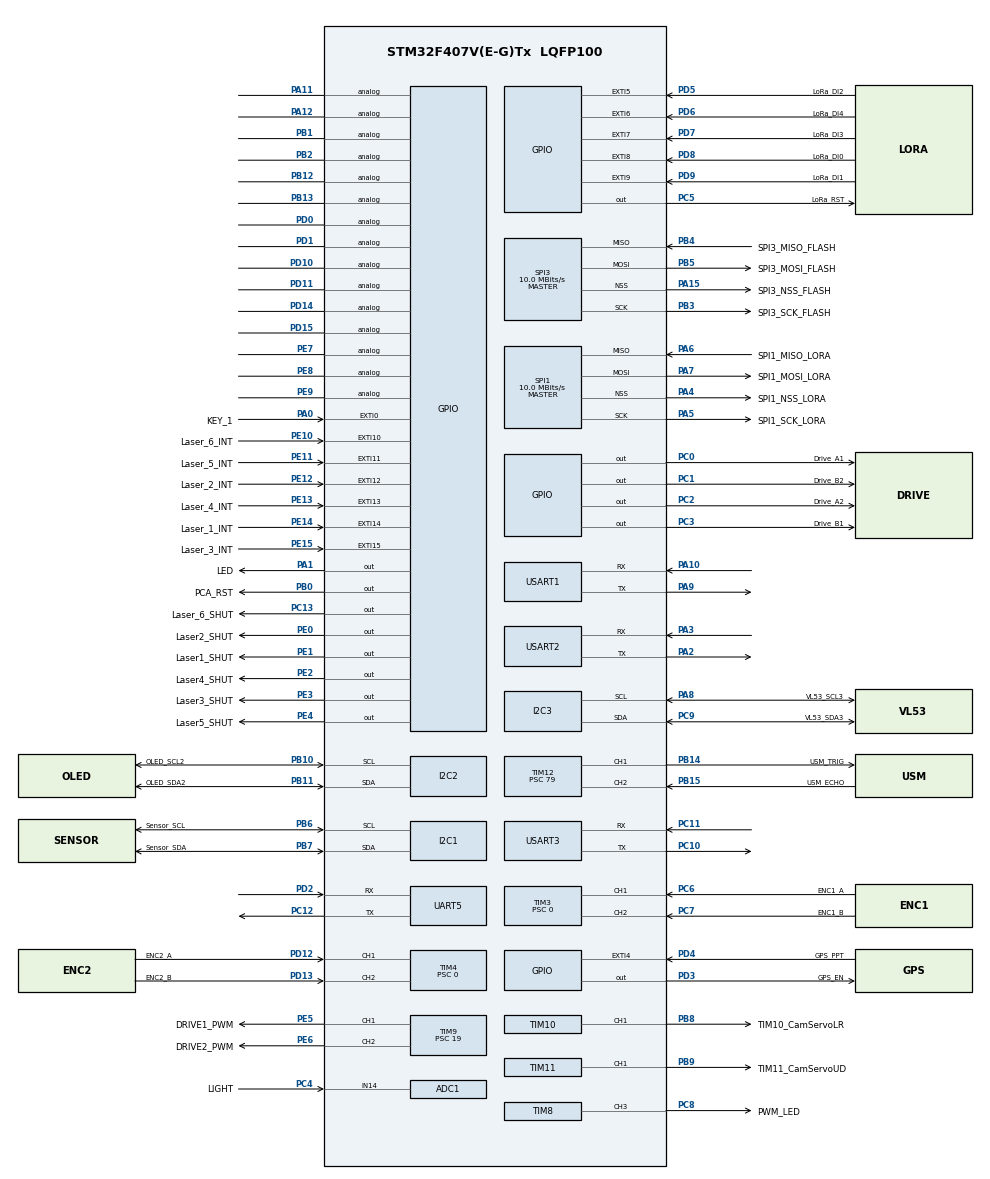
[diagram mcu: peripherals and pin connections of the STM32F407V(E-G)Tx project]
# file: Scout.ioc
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ADC1.Channel-1\#ChannelRegularConversion=ADC_CHANNEL_14
ADC1.Channel-4\#ChannelRegularConversion=ADC_CHANNEL_TEMPSENSOR
ADC1.Channel-5\#ChannelRegularConversion=ADC_CHANNEL_VREFINT
ADC1.ClockPrescaler=ADC_CLOCK_SYNC_PCLK_DIV8
ADC1.ContinuousConvMode=ENABLE
ADC1.InjNumberOfConversion=0
ADC1.NbrOfConversion=3
ADC1.NbrOfConversionFlag=1
ADC1.Rank-1\#ChannelRegularConversion=1
ADC1.Rank-4\#ChannelRegularConversion=2
ADC1.Rank-5\#ChannelRegularConversion=3
ADC1.SamplingTime-1\#ChannelRegularConversion=ADC_SAMPLETIME_28CYCLES
ADC1.SamplingTime-4\#ChannelRegularConversion=ADC_SAMPLETIME_28CYCLES
ADC1.SamplingTime-5\#ChannelRegularConversion=ADC_SAMPLETIME_28CYCLES
ADC1.master=1
I2C1.I2C_Mode=I2C_Fast
I2C2.I2C_Mode=I2C_Fast
I2C3.I2C_Mode=I2C_Fast
IWDG.Prescaler=IWDG_PRESCALER_16
IWDG.Reload=2000
Mcu.Family=STM32F4
Mcu.Name=STM32F407V(E-G)Tx
Mcu.Package=LQFP100
NVIC.ADC_IRQn=true\:0\:0\:false\:false\:true\:true\:true\:true
NVIC.EXTI0_IRQn=true\:15\:0\:true\:false\:true\:true\:true\:true
NVIC.EXTI15_10_IRQn=true\:5\:0\:true\:false\:true\:true\:true\:true
NVIC.EXTI9_5_IRQn=true\:5\:0\:true\:false\:true\:true\:true\:true
NVIC.HASH_RNG_IRQn=true\:9\:0\:true\:false\:true\:true\:true\:true
NVIC.I2C1_ER_IRQn=true\:3\:0\:true\:false\:true\:true\:true\:true
NVIC.I2C1_EV_IRQn=true\:0\:0\:false\:false\:true\:true\:true\:true
NVIC.I2C2_ER_IRQn=true\:3\:0\:true\:false\:true\:true\:true\:true
NVIC.I2C2_EV_IRQn=true\:0\:0\:false\:false\:true\:true\:true\:true
NVIC.I2C3_ER_IRQn=true\:3\:0\:true\:false\:true\:true\:true\:true
NVIC.I2C3_EV_IRQn=true\:0\:0\:false\:false\:true\:true\:true\:true
NVIC.PriorityGroup=NVIC_PRIORITYGROUP_4
NVIC.SPI1_IRQn=true\:1\:0\:true\:false\:true\:true\:true\:true
NVIC.SPI3_IRQn=true\:1\:0\:true\:false\:true\:true\:true\:true
NVIC.TIM1_BRK_TIM9_IRQn=true\:6\:0\:true\:false\:true\:true\:true\:true
NVIC.TIM1_TRG_COM_TIM11_IRQn=true\:7\:0\:true\:false\:true\:true\:true\:true
NVIC.TIM1_UP_TIM10_IRQn=true\:7\:0\:true\:false\:true\:true\:true\:true
NVIC.TIM6_DAC_IRQn=true\:6\:0\:true\:false\:true\:true\:true\:true
NVIC.TIM7_IRQn=true\:6\:0\:true\:false\:true\:true\:true\:true
NVIC.TIM8_BRK_TIM12_IRQn=true\:7\:0\:true\:false\:true\:true\:true\:true
NVIC.TIM8_TRG_COM_TIM14_IRQn=true\:0\:0\:false\:false\:true\:true\:true\:true
NVIC.TIM8_UP_TIM13_IRQn=true\:7\:0\:true\:false\:true\:true\:true\:true
NVIC.UART5_IRQn=true\:2\:0\:true\:false\:true\:true\:true\:true
NVIC.USART1_IRQn=true\:2\:0\:true\:false\:true\:true\:true\:true
NVIC.USART2_IRQn=true\:2\:0\:true\:false\:true\:true\:true\:true
NVIC.USART3_IRQn=true\:2\:0\:true\:false\:true\:true\:true\:true
PA0-WKUP.GPIO_Label=KEY_1
PA0-WKUP.GPIO_ModeDefaultEXTI=GPIO_MODE_IT_RISING
PA0-WKUP.GPIO_PuPd=GPIO_PULLDOWN
PA0-WKUP.Signal=GPXTI0
PA1.GPIO_Label=LED
PA1.GPIO_ModeDefaultOutputPP=GPIO_MODE_OUTPUT_OD
PA1.GPIO_PuPd=GPIO_NOPULL
PA1.PinState=GPIO_PIN_SET
PA1.Signal=GPIO_Output
PA10.Mode=Asynchronous
PA10.Signal=USART1_RX
PA11.Signal=GPIO_Analog
PA12.Signal=GPIO_Analog
PA13.Mode=Serial_Wire
PA13.Signal=SYS_JTMS-SWDIO
PA14.Mode=Serial_Wire
PA14.Signal=SYS_JTCK-SWCLK
PA15.GPIO_Label=SPI3_NSS_FLASH
PA15.Mode=NSS_Signal_Hard_Output
PA15.Signal=SPI3_NSS
PA2.Mode=Asynchronous
PA2.Signal=USART2_TX
PA3.Mode=Asynchronous
PA3.Signal=USART2_RX
PA4.GPIO_Label=SPI1_NSS_LORA
PA4.Mode=NSS_Signal_Hard_Output
PA4.Signal=SPI1_NSS
PA5.GPIO_Label=SPI1_SCK_LORA
PA5.Mode=Full_Duplex_Master
PA5.Signal=SPI1_SCK
PA6.GPIO_Label=SPI1_MISO_LORA
PA6.Mode=Full_Duplex_Master
PA6.Signal=SPI1_MISO
PA7.GPIO_Label=SPI1_MOSI_LORA
PA7.Mode=Full_Duplex_Master
PA7.Signal=SPI1_MOSI
PA8.GPIO_Label=VL53_SCL3
PA8.Mode=I2C
PA8.Signal=I2C3_SCL
PA9.Mode=Asynchronous
PA9.Signal=USART1_TX
PB0.GPIO_Label=PCA_RST
PB0.GPIO_PuPd=GPIO_PULLUP
PB0.PinState=GPIO_PIN_SET
PB0.Signal=GPIO_Output
PB1.Signal=GPIO_Analog
PB10.GPIO_Label=OLED_SCL2
PB10.Mode=I2C
PB10.Signal=I2C2_SCL
PB11.GPIO_Label=OLED_SDA2
PB11.Mode=I2C
PB11.Signal=I2C2_SDA
PB12.Signal=GPIO_Analog
PB13.Signal=GPIO_Analog
PB14.GPIO_Label=USM_TRIG
PB14.Signal=S_TIM12_CH1
PB15.GPIO_Label=USM_ECHO
PB15.Signal=S_TIM12_CH2
PB2.Signal=GPIO_Analog
PB3.GPIO_Label=SPI3_SCK_FLASH
PB3.Mode=Full_Duplex_Master
PB3.Signal=SPI3_SCK
PB4.GPIO_Label=SPI3_MISO_FLASH
PB4.Mode=Full_Duplex_Master
PB4.Signal=SPI3_MISO
PB5.GPIO_Label=SPI3_MOSI_FLASH
PB5.Mode=Full_Duplex_Master
PB5.Signal=SPI3_MOSI
PB6.GPIO_Label=Sensor_SCL
PB6.Mode=I2C
PB6.Signal=I2C1_SCL
PB7.GPIO_Label=Sensor_SDA
PB7.Mode=I2C
PB7.Signal=I2C1_SDA
PB8.GPIO_Label=TIM10_CamServoLR
PB8.Signal=S_TIM10_CH1
PB9.GPIO_Label=TIM11_CamServoUD
PB9.Signal=S_TIM11_CH1
PC0.GPIO_Label=Drive_A1
PC0.GPIO_PuPd=GPIO_PULLDOWN
PC0.Signal=GPIO_Output
PC1.GPIO_Label=Drive_B2
PC1.GPIO_PuPd=GPIO_PULLDOWN
PC1.Signal=GPIO_Output
PC10.Mode=Asynchronous
PC10.Signal=USART3_TX
PC11.Mode=Asynchronous
PC11.Signal=USART3_RX
PC12.GPIO_Speed=GPIO_SPEED_FREQ_HIGH
PC12.Mode=Asynchronous
PC12.Signal=UART5_TX
PC13-ANTI_TAMP.GPIO_Label=Laser_6_SHUT
PC13-ANTI_TAMP.GPIO_PuPd=GPIO_PULLUP
PC13-ANTI_TAMP.PinState=GPIO_PIN_SET
PC13-ANTI_TAMP.Signal=GPIO_Output
PC14-OSC32_IN.Mode=LSE-External-Oscillator
PC14-OSC32_IN.Signal=RCC_OSC32_IN
PC15-OSC32_OUT.Mode=LSE-External-Oscillator
PC15-OSC32_OUT.Signal=RCC_OSC32_OUT
PC2.GPIO_Label=Drive_A2
PC2.GPIO_PuPd=GPIO_PULLDOWN
PC2.Signal=GPIO_Output
PC3.GPIO_Label=Drive_B1
PC3.GPIO_PuPd=GPIO_PULLDOWN
PC3.Signal=GPIO_Output
PC4.GPIO_Label=LIGHT
PC4.Signal=ADCx_IN14
PC5.GPIO_Label=LoRa_RST
PC5.GPIO_PuPd=GPIO_PULLUP
PC5.PinState=GPIO_PIN_SET
PC5.Signal=GPIO_Output
PC6.GPIO_Label=ENC1_A
PC6.Signal=S_TIM3_CH1
PC7.GPIO_Label=ENC1_B
PC7.Signal=S_TIM3_CH2
PC8.GPIO_Label=PWM_LED
PC8.Signal=S_TIM8_CH3
PC9.GPIO_Label=VL53_SDA3
PC9.Mode=I2C
PC9.Signal=I2C3_SDA
PD0.Signal=GPIO_Analog
PD1.Signal=GPIO_Analog
PD10.Signal=GPIO_Analog
PD11.Signal=GPIO_Analog
PD12.GPIO_Label=ENC2_A
PD12.Signal=S_TIM4_CH1
PD13.GPIO_Label=ENC2_B
PD13.Signal=S_TIM4_CH2
PD14.Signal=GPIO_Analog
PD15.Signal=GPIO_Analog
PD2.GPIO_Speed=GPIO_SPEED_FREQ_HIGH
PD2.Mode=Asynchronous
PD2.Signal=UART5_RX
PD3.GPIO_Label=GPS_EN
PD3.GPIO_PuPd=GPIO_PULLUP
PD3.PinState=GPIO_PIN_SET
PD3.Signal=GPIO_Output
PD4.GPIO_Label=GPS_PPT
PD4.GPIO_ModeDefaultEXTI=GPIO_MODE_EVT_RISING
PD4.GPIO_PuPd=GPIO_PULLDOWN
PD4.Signal=GPXTI4
PD5.GPIO_Label=LoRa_DI2
PD5.GPIO_PuPd=GPIO_PULLDOWN
PD5.Signal=GPXTI5
PD6.GPIO_Label=LoRa_DI4
PD6.GPIO_PuPd=GPIO_PULLDOWN
PD6.Signal=GPXTI6
PD7.GPIO_Label=LoRa_DI3
PD7.GPIO_PuPd=GPIO_PULLDOWN
PD7.Signal=GPXTI7
PD8.GPIO_Label=LoRa_DI0
PD8.GPIO_PuPd=GPIO_PULLDOWN
PD8.Signal=GPXTI8
PD9.GPIO_Label=LoRa_DI1
PD9.GPIO_PuPd=GPIO_PULLDOWN
PD9.Signal=GPXTI9
PE0.GPIO_Label=Laser2_SHUT
PE0.GPIO_PuPd=GPIO_PULLUP
PE0.PinState=GPIO_PIN_SET
PE0.Signal=GPIO_Output
PE1.GPIO_Label=Laser1_SHUT
PE1.GPIO_PuPd=GPIO_PULLUP
PE1.PinState=GPIO_PIN_SET
PE1.Signal=GPIO_Output
PE10.GPIO_Label=Laser_6_INT
PE10.GPIO_PuPd=GPIO_PULLUP
PE10.Signal=GPXTI10
PE11.GPIO_Label=Laser_5_INT
PE11.GPIO_PuPd=GPIO_PULLUP
PE11.Signal=GPXTI11
PE12.GPIO_Label=Laser_2_INT
PE12.GPIO_PuPd=GPIO_PULLUP
PE12.Signal=GPXTI12
PE13.GPIO_Label=Laser_4_INT
PE13.GPIO_PuPd=GPIO_PULLUP
PE13.Signal=GPXTI13
PE14.GPIO_Label=Laser_1_INT
PE14.GPIO_PuPd=GPIO_PULLUP
PE14.Signal=GPXTI14
PE15.GPIO_Label=Laser_3_INT
PE15.GPIO_PuPd=GPIO_PULLUP
PE15.Signal=GPXTI15
PE2.GPIO_Label=Laser4_SHUT
PE2.GPIO_PuPd=GPIO_PULLUP
PE2.PinState=GPIO_PIN_SET
PE2.Signal=GPIO_Output
PE3.GPIO_Label=Laser3_SHUT
PE3.GPIO_PuPd=GPIO_PULLUP
PE3.PinState=GPIO_PIN_SET
PE3.Signal=GPIO_Output
PE4.GPIO_Label=Laser5_SHUT
PE4.GPIO_PuPd=GPIO_PULLUP
PE4.PinState=GPIO_PIN_SET
PE4.Signal=GPIO_Output
PE5.GPIO_Label=DRIVE1_PWM
PE5.Signal=S_TIM9_CH1
PE6.GPIO_Label=DRIVE2_PWM
PE6.Signal=S_TIM9_CH2
PE7.Signal=GPIO_Analog
PE8.Signal=GPIO_Analog
PE9.Signal=GPIO_Analog
PH0-OSC_IN.Mode=HSE-External-Oscillator
PH0-OSC_IN.Signal=RCC_OSC_IN
PH1-OSC_OUT.Mode=HSE-External-Oscillator
PH1-OSC_OUT.Signal=RCC_OSC_OUT
ProjectManager.HeapSize=0x200
ProjectManager.StackSize=0x400
ProjectManager.TargetToolchain=STM32CubeIDE
RCC.48MHZClocksFreq_Value=40000000
RCC.AHBFreq_Value=160000000
RCC.APB1CLKDivider=RCC_HCLK_DIV4
RCC.APB1Freq_Value=40000000
RCC.APB1TimFreq_Value=80000000
RCC.APB2CLKDivider=RCC_HCLK_DIV2
RCC.APB2Freq_Value=80000000
RCC.APB2TimFreq_Value=160000000
RCC.CortexFreq_Value=160000000
RCC.EnbaleCSS=true
RCC.HCLKFreq_Value=160000000
RCC.HSE_Timout=250
RCC.HSE_VALUE=8000000
RCC.HSI_VALUE=16000000
RCC.PLLM=8
RCC.PLLN=320
RCC.PLLQ=8
RCC.PLLSourceVirtual=RCC_PLLSOURCE_HSE
RCC.RCC_RTC_Clock_Source=RCC_RTCCLKSOURCE_LSE
RCC.RCC_RTC_Clock_SourceVirtual=RCC_RTCCLKSOURCE_LSI
RCC.RCC_RTC_Clock_Source_FROM_HSE=RCC_RTCCLKSOURCE_HSE_DIV28
RCC.SYSCLKFreq_VALUE=160000000
RCC.SYSCLKSource=RCC_SYSCLKSOURCE_PLLCLK
RCC.VCOOutputFreq_Value=320000000
SH.ADCx_IN14.0=ADC1_IN14,IN14
SH.S_TIM10_CH1.0=TIM10_CH1,PWM Generation1 CH1
SH.S_TIM11_CH1.0=TIM11_CH1,PWM Generation1 CH1
SH.S_TIM12_CH1.0=TIM12_CH1,PWM Generation1 CH1
SH.S_TIM12_CH2.0=TIM12_CH2,Input_Capture2_from_TI2
SH.S_TIM3_CH1.0=TIM3_CH1,Encoder_Interface
SH.S_TIM3_CH2.0=TIM3_CH2,Encoder_Interface
SH.S_TIM4_CH1.0=TIM4_CH1,Encoder_Interface
SH.S_TIM4_CH2.0=TIM4_CH2,Encoder_Interface
SH.S_TIM8_CH3.0=TIM8_CH3,PWM Generation3 CH3
SH.S_TIM9_CH1.0=TIM9_CH1,PWM Generation1 CH1
SH.S_TIM9_CH2.0=TIM9_CH2,PWM Generation2 CH2
SPI1.BaudRatePrescaler=SPI_BAUDRATEPRESCALER_8
SPI1.CLKPhase=SPI_PHASE_1EDGE
SPI1.CLKPolarity=SPI_POLARITY_LOW
SPI1.CalculateBaudRate=10.0 MBits/s
SPI1.Direction=SPI_DIRECTION_2LINES
SPI1.Mode=SPI_MODE_MASTER
SPI1.VirtualNSS=VM_NSSHARD
SPI1.VirtualType=VM_MASTER
SPI3.BaudRatePrescaler=SPI_BAUDRATEPRESCALER_4
SPI3.CalculateBaudRate=10.0 MBits/s
SPI3.Direction=SPI_DIRECTION_2LINES
SPI3.Mode=SPI_MODE_MASTER
SPI3.VirtualNSS=VM_NSSHARD
SPI3.VirtualType=VM_MASTER
TIM10.Channel=TIM_CHANNEL_1
TIM10.Period=39999
TIM10.Prescaler=79
TIM10.Pulse=2250
TIM11.Channel=TIM_CHANNEL_1
TIM11.Period=39999
TIM11.Prescaler=79
TIM11.Pulse=2250
TIM12.Channel-Input_Capture2_from_TI2=TIM_CHANNEL_2
TIM12.Channel-PWM\ Generation1\ CH1=TIM_CHANNEL_1
TIM12.Period=65535
TIM12.Prescaler=79
TIM12.Pulse-PWM\ Generation1\ CH1=1
TIM13.Channel=TIM_CHANNEL_1
TIM13.Period=49999
TIM13.Prescaler=159
TIM13.Pulse=24999
TIM3.AutoReloadPreload=TIM_AUTORELOAD_PRELOAD_DISABLE
TIM3.EncoderMode=TIM_ENCODERMODE_TI12
TIM3.IC1Filter=5
TIM3.IC2Filter=5
TIM3.Prescaler=0
TIM4.AutoReloadPreload=TIM_AUTORELOAD_PRELOAD_DISABLE
TIM4.EncoderMode=TIM_ENCODERMODE_TI12
TIM4.IC1Filter=5
TIM4.IC2Filter=5
TIM4.Prescaler=0
TIM6.Prescaler=79
TIM6.TIM_MasterOutputTrigger=TIM_TRGO_UPDATE
TIM7.AutoReloadPreload=TIM_AUTORELOAD_PRELOAD_ENABLE
TIM7.Period=49999
TIM7.Prescaler=1599
TIM7.TIM_MasterOutputTrigger=TIM_TRGO_UPDATE
TIM8.AutoReloadPreload=TIM_AUTORELOAD_PRELOAD_DISABLE
TIM8.Channel-PWM\ Generation3\ CH3=TIM_CHANNEL_3
TIM8.Period=1999
TIM8.Prescaler=39
TIM8.RepetitionCounter=4
TIM8.TIM_MasterOutputTrigger=TIM_TRGO_RESET
TIM8.TIM_MasterSlaveMode=TIM_MASTERSLAVEMODE_DISABLE
TIM9.Channel-PWM\ Generation1\ CH1=TIM_CHANNEL_1
TIM9.Channel-PWM\ Generation2\ CH2=TIM_CHANNEL_2
TIM9.Period=3999
TIM9.Prescaler=19
UART5.VirtualMode=Asynchronous
USART1.VirtualMode=VM_ASYNC
USART2.Parity=PARITY_EVEN
USART2.VirtualMode=VM_ASYNC
USART3.VirtualMode=VM_ASYNC
VP_ADC1_TempSens_Input.Mode=IN-TempSens
VP_ADC1_Vref_Input.Mode=IN-Vrefint
VP_CRC_VS_CRC.Mode=CRC_Activate
VP_IWDG_VS_IWDG.Mode=IWDG_Activate
VP_RNG_VS_RNG.Mode=RNG_Activate
VP_TIM10_VS_ClockSourceINT.Mode=Enable_Timer
VP_TIM11_VS_ClockSourceINT.Mode=Enable_Timer
VP_TIM12_VS_ClockSourceINT.Mode=Internal
VP_TIM12_VS_ClockSourceITR.Mode=TriggerSource_ITR2
VP_TIM12_VS_ControllerModeTrigger.Mode=Trigger Mode
VP_TIM12_VS_OPM.Mode=OPM_bit
VP_TIM13_VS_ClockSourceINT.Mode=Enable_Timer
VP_TIM13_VS_no_output1.Mode=Output Compare1 No Output
VP_TIM6_VS_ClockSourceINT.Mode=Enable_Timer
VP_TIM7_VS_ClockSourceINT.Mode=Enable_Timer
VP_TIM9_VS_ClockSourceINT.Mode=Internal
board=custom

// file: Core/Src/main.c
/* USER CODE BEGIN Header */
/**
 ******************************************************************************
 * @file           : main.c
 * @brief          : Main program body
 ******************************************************************************
 * @attention
 *
 * Copyright (c) 2023 STMicroelectronics.
 * All rights reserved.
 *
 * This software is licensed under terms that can be found in the LICENSE file
 * in the root directory of this software component.
 * If no LICENSE file comes with this software, it is provided AS-IS.
 *
 ******************************************************************************
 */
/* USER CODE END Header */
#include "main.h"
#include "adc.h"
#include "crc.h"
#include "i2c.h"
#include "iwdg.h"
#include "rng.h"
#include "spi.h"
#include "tim.h"
#include "usart.h"
#include "gpio.h"

/* USER CODE BEGIN Includes */
#include "Objects.h"
/* USER CODE END Includes */

/* USER CODE BEGIN PV */
//variables for time based-----------------------------------------------------
volatile uint32_t mainTimeTick = 0;

//variables for enable sensor request and other options------------------------
volatile uint32_t DevicesEnableMask = 0;
volatile uint32_t laserReqMask = 0;
uint32_t optionMask = 0;
//objects: IO ports
extern I2C_IRQ_Conn_t I2CSensors;		//i2c1 bus for sensors
extern I2C_IRQ_Conn_t I2CLasers;		//i2c3 bus for VL53L01 sensors
extern SPI_Conn_TWO_t SPI_LoRa;			//SPI1 for LoRa radio
extern SPI_Conn_TWO_t SPI_Flash;		//SPI3 for flash
extern USART_FullDuplex_t USART_Orange;	//usart1 bus for Orange Pi Zero2 connection
extern USART_FullDuplex_t USART_CLI;			//usart2 bus for external connection CLI
extern USART_FullDuplex_t USART_UNO;		//usart3 bus for external connection
extern USART_FullDuplex_t UART_GPS;				//uart5 bus for GPS connection
//sensors----------------------------------------------------------------------
extern TCA9548A_t tca9548;					//i2c multiplexer
extern VL53L0x_t LaserFrontLeft;		//laser sensor VL53L01 front left place
extern VL53L0x_t LaserFrontRight;		//laser sensor VL53L01 front left place
extern VL53L0x_t LaserMidLeft;			//laser sensor VL53L01 front left place
extern VL53L0x_t LaserMidRight;			//laser sensor VL53L01 front left place
extern VL53L0x_t LaserBackLeft;			//laser sensor VL53L01 front left place
extern VL53L0x_t LaserBackRight;		//laser sensor VL53L01 front left place
extern ADXL345_t adxl345;				//accelerometer
extern ITG3205_t itg3205;				//gyroscope
extern QMC5883L_t qmc5883; 				//magnetometer
extern BME280_t bme280;					//ambient sensor
extern INA219_t ina219;					//current voltage power sensor
extern HC_SR04_t USMrange;
//objects------------------------------------------------------------------------
extern Drive_t Drive;
extern PID_M_t PidMoto_L;
extern PID_M_t PidMoto_R;
extern PID_MF_t PidMotoFilter_L;
extern PID_MF_t PidMotoFilter_R;
Camera_t camera;		//camera's servo drives
uint16_t leftWheelPWM;
uint16_t rightWheelPWM;
Quaternion_t quatHabr;
EulerAngles_t angHabr;
Quaternion_t quatMadg;
EulerAngles_t angMadg;
Quaternion_t quatMah;
EulerAngles_t angMah;
FusionEuler euler;
FusionAhrs ahrs;

uint16_t headLightsLevel = 0;
uint16_t ambientLightLevel = 0;
uint16_t mcuTemp = 0;
uint16_t mcuVoltage = 0;
/* USER CODE END PV */

void SystemClock_Config(void);
/* USER CODE BEGIN PFP */
static inline void EnableOption(uint32_t reg, uint32_t option) {
	SET_BIT(reg, option);
}
static inline void DisableOption(uint32_t reg, uint32_t option) {
	CLEAR_BIT(reg, option);
}
static inline uint32_t IsOptionEnable(uint32_t reg, uint32_t option) {
	return reg & option;
}
uint16_t SideLightsControl(uint16_t ambient, uint8_t en);
void WheelStop(GPIO_TypeDef *port, uint32_t pin1, uint32_t pin2);
void WheelForward(GPIO_TypeDef *port, uint32_t pinA, uint32_t pinB);
void WheelBackward(GPIO_TypeDef *port, uint32_t pinA, uint32_t pinB);
/* USER CODE END PFP */

int main(void) {

	/* MCU Configuration--------------------------------------------------------*/

	/* Reset of all peripherals, Initializes the Flash interface and the Systick. */
	LL_APB2_GRP1_EnableClock(LL_APB2_GRP1_PERIPH_SYSCFG);
	LL_APB1_GRP1_EnableClock(LL_APB1_GRP1_PERIPH_PWR);

	/* System interrupt init*/
	NVIC_SetPriorityGrouping(NVIC_PRIORITYGROUP_4);

	/* Configure the system clock */
	SystemClock_Config();

	/* Initialize all configured peripherals */
	MX_GPIO_Init();
	MX_CRC_Init();
	MX_RNG_Init();
	MX_SPI1_Init();
	MX_SPI3_Init();
	MX_I2C1_Init();
	MX_I2C2_Init();
	MX_I2C3_Init();
	MX_USART1_UART_Init();
	MX_USART2_UART_Init();
	MX_USART3_UART_Init();
	MX_UART5_Init();
	MX_TIM3_Init();
	MX_TIM4_Init();
	MX_TIM9_Init();
	MX_TIM10_Init();
	MX_TIM11_Init();
	MX_TIM12_Init();
	MX_TIM8_Init();
	MX_TIM6_Init();
	MX_TIM7_Init();
	MX_TIM13_Init();
	MX_ADC1_Init();
	//MX_IWDG_Init();
	/* USER CODE BEGIN 2 */
	SysTick_Config(SystemCoreClock / 1000);	//1ms tick
	TIM10->CCR1 = camera.posH = Servo_Init(&camera.srvLR, SG90_MIN, SG90_MAX,
	    10);
	TIM11->CCR1 = camera.posV = Servo_Init(&camera.srvUD, SG90_MIN, SG90_MAX,
	    10);

	HardwareInit();

	PID_MotoInit(6, 16, 0.75, 25, &PidMoto_L);
	PID_MotoInit(6, 16, 0.75, 25, &PidMoto_R);

	uint8_t stbus;
	LL_GPIO_ResetOutputPin(Laser1_SHUT_GPIO_Port, Laser1_SHUT_Pin | Laser2_SHUT_Pin | Laser3_SHUT_Pin |
			Laser4_SHUT_Pin | Laser5_SHUT_Pin);
	LL_GPIO_ResetOutputPin(Laser6_SHUT_GPIO_Port, Laser6_SHUT_Pin);
	LL_mDelay(5);
	LL_GPIO_SetOutputPin(Laser1_SHUT_GPIO_Port, Laser1_SHUT_Pin | Laser2_SHUT_Pin | Laser3_SHUT_Pin |
			Laser4_SHUT_Pin | Laser5_SHUT_Pin);
	LL_GPIO_SetOutputPin(Laser6_SHUT_GPIO_Port, Laser6_SHUT_Pin);
	LL_mDelay(5);
	do {
		stbus = TCA9548A_SetChannels(&I2CLasers, &tca9548, ~(TCA9548A_CH0 || TCA9548A_CH1 || TCA9548A_CH2 || TCA9548A_CH3 ||
		    TCA9548A_CH4 || TCA9548A_CH5 || TCA9548A_CH6 || TCA9548A_CH7));
	} while (!stbus);			// init i2c multiplexor
	do {
		stbus = TCA9548A_SetChannels(&I2CLasers, &tca9548, TCA9548A_CH0);
	} while (!stbus);	// enable channel 0

	/*do {
		stbus = VL53L0x_Init(&I2CLasers, &LaserBackLeft);
	} while (!stbus);	*/			// init laser back left
	do {
		stbus = TCA9548A_SetChannels(&I2CLasers, &tca9548, TCA9548A_CH1);
	} while (!stbus);	// enable channel 1
	/*do {
		stbus = VL53L0x_Init(&I2CLasers, &LaserBackRight);
	} while (!stbus);	*/			// init laser back right
	do {
		stbus = TCA9548A_SetChannels(&I2CLasers, &tca9548, TCA9548A_CH2);
	} while (!stbus);	// enable channel 2
	/*do {
		stbus = VL53L0x_Init(&I2CLasers, &LaserMidRight);
	} while (!stbus);		*/		// init laser mid right
	do {
		stbus = TCA9548A_SetChannels(&I2CLasers, &tca9548, TCA9548A_CH3);
	} while (!stbus);	// enable channel 3
	/*do {
		stbus = VL53L0x_Init(&I2CLasers, &LaserFrontRight);
	} while (!stbus);	*/			// init laser front right
	do {
		stbus = TCA9548A_SetChannels(&I2CLasers, &tca9548, TCA9548A_CH4);
	} while (!stbus);	// enable channel 4
	/*do {
		stbus = VL53L0x_Init(&I2CLasers, &LaserFrontLeft);
	} while (!stbus);	*/			// init laser front left
	do {
		stbus = TCA9548A_SetChannels(&I2CLasers, &tca9548, TCA9548A_CH5);
	} while (!stbus);	// enable channel 5
	/*do {
		stbus = VL53L0x_Init(&I2CLasers, &LaserMidLeft);
	} while (!stbus);*/				// init laser mid left
	/*do {
		stbus = ADXL345_Init(&I2CSensors, &adxl345);
	} while (!stbus);			// init accelerometer pass
	do {
		stbus = QMC5883L_Init(&I2CSensors, &qmc5883);
	} while (!stbus);		// init magnetometer pass
	do {
		stbus = ITG3205_Init(&I2CSensors, &itg3205);
	} while (!stbus);			// init gyroscope

	do {
		stbus = INA219_Init(&I2CSensors, &ina219);
	} while (!stbus);				// init power sensor
	do {
		stbus = BME280_Init(&I2CSensors, &bme280);
	} while (!stbus);				// init ambient sensor pass

	FusionAhrsInitialise(&ahrs);*/
	/* USER CODE END 2 */

	/* Infinite loop */
	/* USER CODE BEGIN WHILE */
	while (1) {

		/*if (laserReqMask) {
			switch (laserReqMask) {
			case 1:	// enable channel 0
				if (TCA9548A_SetChannels(&I2CLasers, &tca9548, TCA9548A_CH0)) {
					laserReqMask = 2;
				}
				break;
			case 2:
				if (VL53_ReadRangeSingle(&I2CLasers, &LaserBackLeft)) {
					laserReqMask = 6;
				}
				break;
			case 3:	//
				if (VL53_StartContinuous(&I2CLasers, &LaserBackLeft, 30)) {
					laserReqMask = 4;
				}
				break;
			case 4:
				if (VL53_readRangeContinuousMillimeters(&I2CLasers, &LaserBackLeft)) {
					laserReqMask = 5;
				}
				break;
			case 5:
				if (VL53_StopContinuous(&I2CLasers, &LaserBackLeft)) {
					laserReqMask = 6;
				}
				break;
			case 6:	// enable channel 1
				if (TCA9548A_SetChannels(&I2CLasers, &tca9548, TCA9548A_CH1)) {
					laserReqMask = 7;
				}
				break;
			case 7:
				if (VL53_ReadRangeSingle(&I2CLasers, &LaserBackRight)) {
					laserReqMask = 11;
				}
				break;
			case 8:
				if (VL53_StartContinuous(&I2CLasers, &LaserBackRight, 30)) {
					laserReqMask = 9;
				}
				break;
			case 9:
				if (VL53_readRangeContinuousMillimeters(&I2CLasers, &LaserBackRight)) {
					laserReqMask = 10;
				}
				break;
			case 10:
				if (VL53_StopContinuous(&I2CLasers, &LaserBackRight)) {
					laserReqMask = 11;
				}
				break;
			case 11:	// enable channel 2
				if (TCA9548A_SetChannels(&I2CLasers, &tca9548, TCA9548A_CH2)) {
					laserReqMask = 12;
				}
				break;
			case 12:
				if (VL53_ReadRangeSingle(&I2CLasers, &LaserMidRight)) {
					laserReqMask = 16;
				}
				break;
			case 13:	// init laser mid right
				if (VL53_StartContinuous(&I2CLasers, &LaserMidRight, 30)) {
					laserReqMask = 14;
				}
				break;
			case 14:
				if (VL53_readRangeContinuousMillimeters(&I2CLasers, &LaserMidRight)) {
					laserReqMask = 15;
				}
				break;
			case 15:
				if (VL53_StopContinuous(&I2CLasers, &LaserMidRight)) {
					laserReqMask = 16;
				}
				break;
			case 16:	// enable channel 3
				if (TCA9548A_SetChannels(&I2CLasers, &tca9548, TCA9548A_CH3)) {
					laserReqMask = 17;
				}
				break;
			case 17:
				if (VL53_ReadRangeSingle(&I2CLasers, &LaserFrontRight)) {
					laserReqMask = 21;
				}
				break;
			case 18:	// init laser front right
				if (VL53_StartContinuous(&I2CLasers, &LaserFrontRight, 30)) {
					laserReqMask = 19;
				}
				break;
			case 19:
				if (VL53_readRangeContinuousMillimeters(&I2CLasers, &LaserFrontRight)) {
					laserReqMask = 20;
				}
				break;
			case 20:
				if (VL53_StopContinuous(&I2CLasers, &LaserFrontRight)) {
					laserReqMask = 21;
				}
				break;
			case 21:	// enable channel 4
				if (TCA9548A_SetChannels(&I2CLasers, &tca9548, TCA9548A_CH4)) {
					laserReqMask = 22;
				}
				break;
			case 22:
				if (VL53_ReadRangeSingle(&I2CLasers, &LaserFrontLeft)) {
					laserReqMask = 26;
				}
				break;
			case 23:	// init laser front left
				if (VL53_StartContinuous(&I2CLasers, &LaserFrontLeft, 30)) {
					laserReqMask = 24;
				}
				break;
			case 24:
				if (VL53_readRangeContinuousMillimeters(&I2CLasers, &LaserFrontLeft)) {
					laserReqMask = 25;
				}
				break;
			case 25:
				if (VL53_StopContinuous(&I2CLasers, &LaserFrontLeft)) {
					laserReqMask = 26;
				}
				break;
			case 26:	// enable channel 5
				if (TCA9548A_SetChannels(&I2CLasers, &tca9548, TCA9548A_CH5)) {
					laserReqMask = 27;
				}
				break;
			case 27:
				if (VL53_ReadRangeSingle(&I2CLasers, &LaserMidLeft)) {
					laserReqMask = 0;
				}
				break;
			case 28:	// init laser front left
				if (VL53_StartContinuous(&I2CLasers, &LaserMidLeft, 30)) {
					laserReqMask = 29;
				}
				break;
			case 29:
				if (VL53_readRangeContinuousMillimeters(&I2CLasers, &LaserMidLeft)) {
					laserReqMask = 30;
				}
				break;
			case 30:
				if (VL53_StopContinuous(&I2CLasers, &LaserMidLeft)) {
					laserReqMask = 0;
				}
				break;
			default:
				laserReqMask = 0;
				break;
			}
		}
*/
		/*if (IsOptionEnable(DevicesEnableMask, ADXL_REQ_MASK)) {
			uint8_t st;
			st = ADXL345_GetData(&I2CSensors, &adxl345);
			if (st) {
				DisableOption(DevicesEnableMask, ADXL_REQ_MASK);
				EnableOption(DevicesEnableMask, QMC_REQ_MASK);
			}
		}
		if (IsOptionEnable(DevicesEnableMask, ITG_REQ_MASK)) {
			uint8_t st;
			st = ITG3205_GetData(&I2CSensors, &itg3205);
			if (st) {
				DisableOption(DevicesEnableMask, ITG_REQ_MASK);
				EnableOption(DevicesEnableMask, QMC_REQ_MASK);
			}
		}
		if (IsOptionEnable(DevicesEnableMask, QMC_REQ_MASK)) {
			uint8_t st;
			st = QMC5883L_GetData(&I2CSensors, &qmc5883);
			if (st) {
				quatMadg = MadgwickAHRSupdate(itg3205.data.X, itg3205.data.Y, -itg3205.data.Z,
														adxl345.data.X, adxl345.data.Y, adxl345.data.Z,
														qmc5883.data.X, qmc5883.data.Y, qmc5883.data.Z);
				angMadg = ToEulerAngles(quatMadg, 1);

				quatMah = MahonyAHRSupdate(itg3205.data.X, itg3205.data.Y, -itg3205.data.Z,
					adxl345.data.X, adxl345.data.Y, adxl345.data.Z,
					qmc5883.data.X, qmc5883.data.Y, qmc5883.data.Z);
				angMah = ToEulerAngles(quatMah, 1);
				quatHabr = AHRSUpdate9(itg3205.data.X, itg3205.data.Y, -itg3205.data.Z,
														adxl345.data.X, adxl345.data.Y, adxl345.data.Z,
														qmc5883.data.X, qmc5883.data.Y, qmc5883.data.Z, 0.05);
				angHabr = ToEulerAngles(quatHabr, 1);
				FusionVector gyro;
				gyro.axis.x = itg3205.data.X;
				gyro.axis.y = itg3205.data.Y;
				gyro.axis.z = -itg3205.data.Z;
				FusionVector accel;
				accel.axis.x = RadiansToDegrees(adxl345.data.X);
				accel.axis.y = RadiansToDegrees(adxl345.data.Y);
				accel.axis.z = RadiansToDegrees(adxl345.data.Z);
				FusionVector mag;
				mag.axis.x = qmc5883.data.X;
				mag.axis.y = qmc5883.data.Y;
				mag.axis.z = qmc5883.data.Z;
				FusionAhrsUpdate(&ahrs, gyro, accel, mag, 0.05);
				euler = FusionQuaternionToEuler(FusionAhrsGetQuaternion(&ahrs));
				DisableOption(DevicesEnableMask, QMC_REQ_MASK);
			}
		}*/
		/*if (IsOptionEnable(DevicesEnableMask, BME_REQ_MASK)) {
			uint8_t st;
			st = BME280_GetData(&I2CSensors, &bme280);
			if (st) {
				DisableOption(DevicesEnableMask, BME_REQ_MASK);
			}
		}
		if (IsOptionEnable(DevicesEnableMask, INA_REQ_MASK)) {
			uint8_t st;
			st = INA219_GetData(&I2CSensors, &ina219);
			if (st) {
				DisableOption(DevicesEnableMask, INA_REQ_MASK);
			}
		}*/
		Drive.SP.pwmLeft = 80;
		Drive.SP.pwmRight = 80;
		Drive.WL.speedSP = WheelSpeedZeroLimiter(Drive.WL.speedSP, Drive.SP.pwmLeft, 20.0, 25.0);
		Drive.WR.speedSP = WheelSpeedZeroLimiter(Drive.WR.speedSP, Drive.SP.pwmRight, 20.0, 25.0);
		WheelForward(Drive_A1_GPIO_Port, Drive_A1_Pin, Drive_A2_Pin);
		WheelForward(Drive_B1_GPIO_Port, Drive_B1_Pin, Drive_B2_Pin);

		TIM8->CCR3 = headLightsLevel = SideLightsControl(ambientLightLevel, 1);
		//CCR1 - right
		//CCR2 - left
		/* USER CODE END WHILE */

		/* USER CODE BEGIN 3 */
		LL_IWDG_ReloadCounter(IWDG);
	}
	/* USER CODE END 3 */
}

void SystemClock_Config(void) {
	LL_FLASH_SetLatency(LL_FLASH_LATENCY_5);
	while (LL_FLASH_GetLatency() != LL_FLASH_LATENCY_5) {
	}
	LL_PWR_SetRegulVoltageScaling(LL_PWR_REGU_VOLTAGE_SCALE1);
	LL_RCC_HSE_Enable();

	/* Wait till HSE is ready */
	while (LL_RCC_HSE_IsReady() != 1) {

	}
	LL_RCC_LSI_Enable();

	/* Wait till LSI is ready */
	while (LL_RCC_LSI_IsReady() != 1) {

	}
	LL_RCC_HSE_EnableCSS();
	LL_RCC_PLL_ConfigDomain_SYS(LL_RCC_PLLSOURCE_HSE, LL_RCC_PLLM_DIV_8, 320,
	LL_RCC_PLLP_DIV_2);
	LL_RCC_PLL_ConfigDomain_48M(LL_RCC_PLLSOURCE_HSE, LL_RCC_PLLM_DIV_8, 320,
	LL_RCC_PLLQ_DIV_8);
	LL_RCC_PLL_Enable();

	/* Wait till PLL is ready */
	while (LL_RCC_PLL_IsReady() != 1) {

	}
	while (LL_PWR_IsActiveFlag_VOS() == 0) {
	}
	LL_RCC_SetAHBPrescaler(LL_RCC_SYSCLK_DIV_1);
	LL_RCC_SetAPB1Prescaler(LL_RCC_APB1_DIV_4);
	LL_RCC_SetAPB2Prescaler(LL_RCC_APB2_DIV_2);
	LL_RCC_SetSysClkSource(LL_RCC_SYS_CLKSOURCE_PLL);

	/* Wait till System clock is ready */
	while (LL_RCC_GetSysClkSource() != LL_RCC_SYS_CLKSOURCE_STATUS_PLL) {

	}
	LL_Init1msTick(160000000);
	LL_SetSystemCoreClock(160000000);
}

/* USER CODE BEGIN 4 */
uint16_t SideLightsControl(uint16_t ambient, uint8_t en) {
	if (en) {
		return 500;
	} else {
		return 0;
	}
}

void WheelStop(GPIO_TypeDef *port, uint32_t pin1, uint32_t pin2) {
	LL_GPIO_ResetOutputPin(port, pin1 | pin2);
}

void WheelForward(GPIO_TypeDef *port, uint32_t pin1, uint32_t pin2) {
	LL_GPIO_ResetOutputPin(port, pin2);
	LL_GPIO_SetOutputPin(port, pin1);
}
void WheelBackward(GPIO_TypeDef *port, uint32_t pin1, uint32_t pin2) {
	LL_GPIO_ResetOutputPin(port, pin1);
	LL_GPIO_SetOutputPin(port, pin2);
}

void HardwareInit(void) {

	TIM3->CCER |= TIM_CCER_CC1E | TIM_CCER_CC2E;
	TIM3->CR1 |= TIM_CR1_CEN;

	TIM4->CCER |= TIM_CCER_CC1E | TIM_CCER_CC2E;
	TIM4->CR1 |= TIM_CR1_CEN;

	TIM7->DIER |= TIM_DIER_UIE;
	TIM7->CR1 |= TIM_CR1_CEN;

	TIM10->CCER |= TIM_CCER_CC1E;
	TIM10->DIER |= TIM_DIER_UIE;
	TIM10->CR1 |= TIM_CR1_CEN;

	TIM11->CCER |= TIM_CCER_CC1E;
	TIM11->DIER |= TIM_DIER_UIE;
	TIM11->CR1 |= TIM_CR1_CEN;

	TIM12->CCER |= TIM_CCER_CC1E | TIM_CCER_CC2E;
	TIM12->DIER |= TIM_DIER_UIE | TIM_DIER_CC2IE;

	TIM8->CCER |= TIM_CCER_CC3E;
	TIM8->BDTR |= TIM_BDTR_MOE;
	TIM8->CR1 |= TIM_CR1_CEN;

	TIM9->CCER |= TIM_CCER_CC1E | TIM_CCER_CC2E;
	TIM9->DIER |= TIM_DIER_UIE;
	TIM9->CR1 |= TIM_CR1_CEN;

	TIM13->CCER |= TIM_CCER_CC1E;
	TIM13->DIER |= TIM_DIER_UIE | TIM_DIER_CC1IE;
	TIM13->CR1 |= TIM_CR1_CEN;

	I2C1->CR2 |= I2C_CR2_ITERREN | I2C_CR2_ITEVTEN;
	I2C1->CR1 |= I2C_CR1_PE;

	/*I2C2->CR2 |= I2C_CR2_ITERREN | I2C_CR2_ITEVTEN;
	 I2C2->CR1 |= I2C_CR1_PE;*/

	I2C3->CR2 |= I2C_CR2_ITERREN | I2C_CR2_ITEVTEN;
	I2C3->CR1 |= I2C_CR1_PE;

	ADC1->CR1 |= ADC_CR1_EOCIE | ADC_CR1_OVRIE;
	ADC1->CR2 |= ADC_CR2_ADON;
	LL_mDelay(5);
	ADC1->CR2 |= ADC_CR2_SWSTART;
}
/* USER CODE END 4 */

void Error_Handler(void) {
	__disable_irq();
	while (1) {
	}
}
